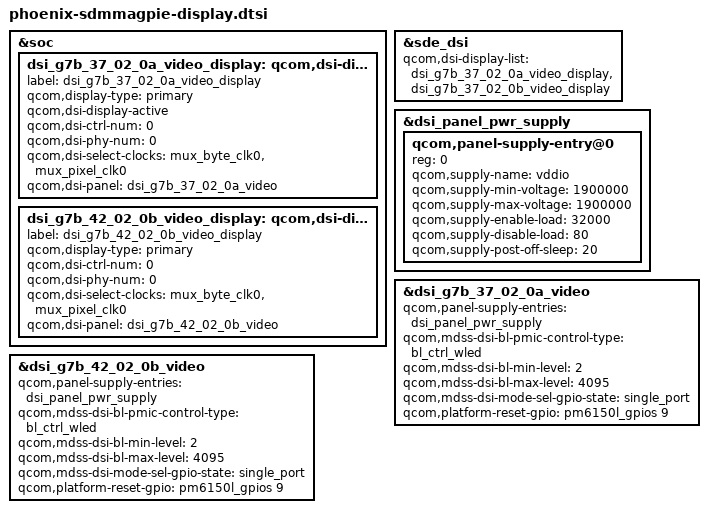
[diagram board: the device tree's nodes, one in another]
/*
 * Copyright (C) 2020 The LineageOS Project
 *
 * this file is for attribution only of phoenix
 * And public attribution of Xiaomi platforms (like G7B and so)
 */

#include "../common/xiaomi-sdmmagpie-display.dtsi"

#include "display/dsi-panel-g7b-37-02-0a-dsc-video.dtsi"
#include "display/dsi-panel-g7b-42-02-0b-dsc-video.dtsi"

&soc {
    dsi_g7b_37_02_0a_video_display: qcom,dsi-display@22 {
        label = "dsi_g7b_37_02_0a_video_display";
        qcom,display-type = "primary";
    
        qcom,dsi-display-active;

        qcom,dsi-ctrl-num = <0>;
        qcom,dsi-phy-num = <0>;
        qcom,dsi-select-clocks = "mux_byte_clk0", "mux_pixel_clk0";

        qcom,dsi-panel = <&dsi_g7b_37_02_0a_video>;
    };

    dsi_g7b_42_02_0b_video_display: qcom,dsi-display@23 {
        label = "dsi_g7b_42_02_0b_video_display";
        qcom,display-type = "primary";

        qcom,dsi-ctrl-num = <0>;
        qcom,dsi-phy-num = <0>;
        qcom,dsi-select-clocks = "mux_byte_clk0", "mux_pixel_clk0";

        qcom,dsi-panel = <&dsi_g7b_42_02_0b_video>;
    };
};

&sde_dsi {
    qcom,dsi-display-list =
        <&dsi_g7b_37_02_0a_video_display
        &dsi_g7b_37_02_0b_video_display>;
};

&dsi_panel_pwr_supply {
    qcom,panel-supply-entry@0 {
        reg = <0>;
        qcom,supply-name = "vddio";
        qcom,supply-min-voltage = <1900000>;
        qcom,supply-max-voltage = <1900000>;
        qcom,supply-enable-load = <32000>;
        qcom,supply-disable-load = <80>;
        qcom,supply-post-off-sleep = <20>;
    };
};

&dsi_g7b_37_02_0a_video {
    qcom,panel-supply-entries = <&dsi_panel_pwr_supply>;
    qcom,mdss-dsi-bl-pmic-control-type = "bl_ctrl_wled";
    qcom,mdss-dsi-bl-min-level = <2>;
    qcom,mdss-dsi-bl-max-level = <4095>;
    qcom,mdss-dsi-mode-sel-gpio-state = "single_port";
    qcom,platform-reset-gpio = <&pm6150l_gpios 9 0>;
};

&dsi_g7b_42_02_0b_video {
    qcom,panel-supply-entries = <&dsi_panel_pwr_supply>;
    qcom,mdss-dsi-bl-pmic-control-type = "bl_ctrl_wled";
    qcom,mdss-dsi-bl-min-level = <2>;
    qcom,mdss-dsi-bl-max-level = <4095>;
    qcom,mdss-dsi-mode-sel-gpio-state = "single_port";
    qcom,platform-reset-gpio = <&pm6150l_gpios 9 0>;
};
